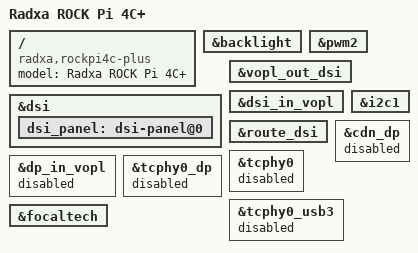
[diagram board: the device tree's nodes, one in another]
/dts-v1/;
/plugin/;

/ {
	model = "Radxa ROCK Pi 4C+";
	compatible = "radxa,rockpi4c-plus","rockchip,rk3399";

	fragment@0 {
		target = <&backlight>;

		__overlay__ {
			status = "okay";
		};
	};

	fragment@1 {
		target = <&pwm2>;

		__overlay__ {
			status = "okay";
		};
	};

	fragment@2 {
		target = <&dsi>;

		__overlay__ {
			status = "okay";
			dsi_panel: dsi-panel@0 {
				status = "okay";
			};
		};
	};

	fragment@3 {
		target = <&vopl_out_dsi>;

		__overlay__ {
			status = "okay";
		};
	};

	fragment@4 {
		target = <&dsi_in_vopl>;

		__overlay__ {
			status = "okay";
		};
	};

	fragment@5 {
		target = <&route_dsi>;

		__overlay__ {
			status = "okay";
		};
	};

	fragment@6 {
		target = <&i2c1>;

		__overlay__ {
			status = "okay";
		};
	};

	fragment@7 {
		target = <&cdn_dp>;

		__overlay__ {
			status = "disabled";
		};
	};

	fragment@8 {
		target = <&tcphy0>;

		__overlay__ {
			status = "disabled";
		};
	};

	fragment@9 {
		target = <&dp_in_vopl>;

		__overlay__ {
			status = "disabled";
		};
	};

	fragment@10 {
		target = <&tcphy0_dp>;

		__overlay__ {
			status = "disabled";
		};
	};

	fragment@11 {
		target = <&tcphy0_usb3>;

		__overlay__ {
			status = "disabled";
		};
	};

	fragment@12 {
		target = <&focaltech>;
		__overlay__ {
			status = "okay";
		};
	};
};
